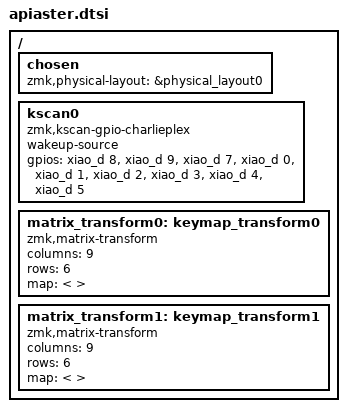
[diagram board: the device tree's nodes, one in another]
#include <dt-bindings/zmk/matrix_transform.h>
#include "apiaster-layouts.dtsi"

/ {
    chosen {
        zmk,physical-layout = &physical_layout0;
    };

    kscan0: kscan0 {
        compatible = "zmk,kscan-gpio-charlieplex";
        wakeup-source;

        gpios = 
            <&xiao_d 8 GPIO_ACTIVE_HIGH>,
            <&xiao_d 9 GPIO_ACTIVE_HIGH>,
            <&xiao_d 7 GPIO_ACTIVE_HIGH>,
            <&xiao_d 0 GPIO_ACTIVE_HIGH>,
            <&xiao_d 1 GPIO_ACTIVE_HIGH>,
            <&xiao_d 2 GPIO_ACTIVE_HIGH>,
            <&xiao_d 3 GPIO_ACTIVE_HIGH>,
            <&xiao_d 4 GPIO_ACTIVE_HIGH>,
            <&xiao_d 5 GPIO_ACTIVE_HIGH>;

        // Removed: <&xiao_d 6 GPIO_ACTIVE_HIGH> (was D10)
        // Removed interrupt pin (which was also D10)
    };

    matrix_transform0: keymap_transform0 {
        compatible = "zmk,matrix-transform";
        columns = <9>;  // Changed from 10
        rows = <6>;
        map = <
            // Your layout must be adjusted here to match 9 columns
            // If not done, ZMK will misinterpret positions
        >;
    };

    matrix_transform1: keymap_transform1 {
        compatible = "zmk,matrix-transform";
        columns = <9>;  // Changed from 10
        rows = <6>;
        map = <
            // Adjust this too if you’re using it
        >;
    };
};
